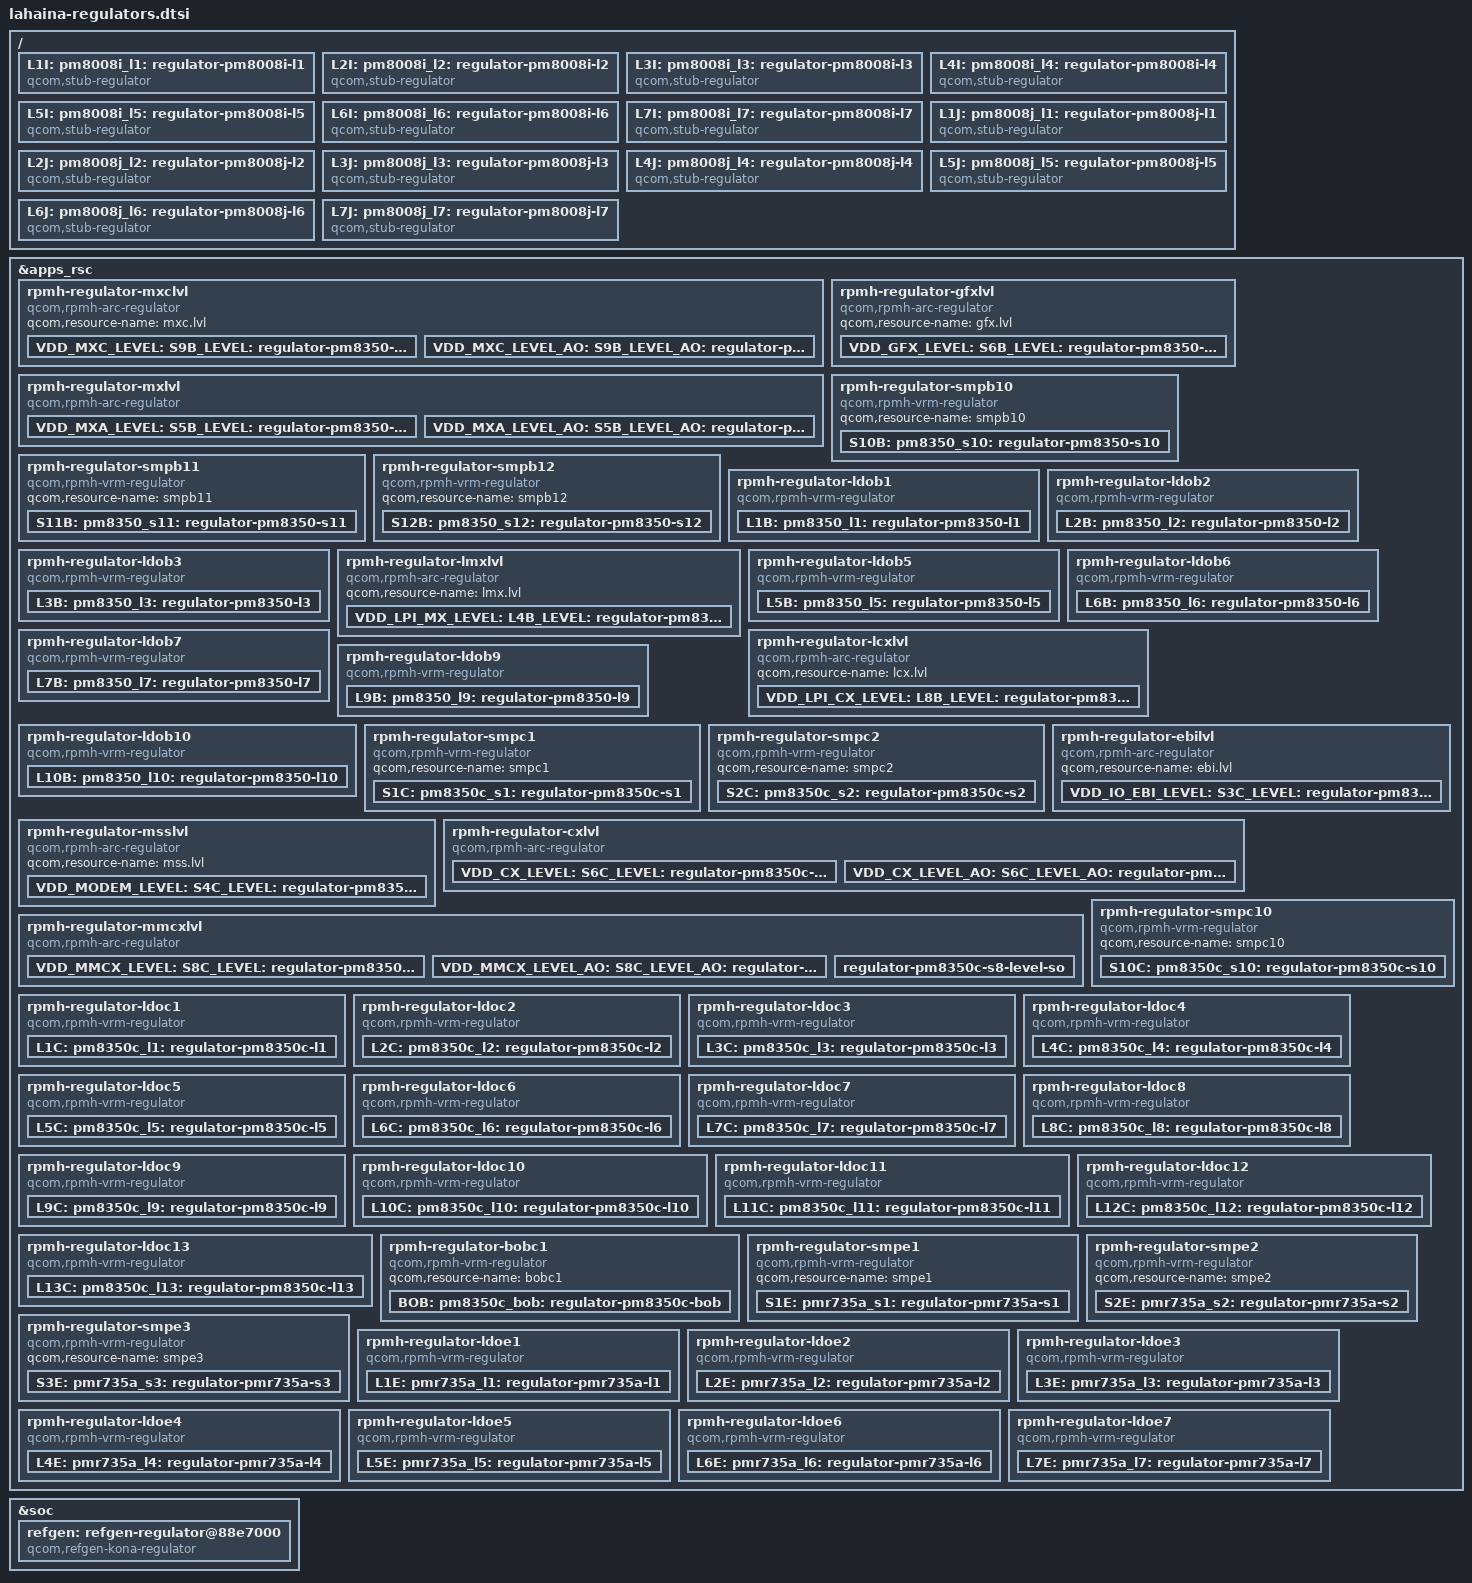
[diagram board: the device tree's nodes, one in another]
#include <dt-bindings/regulator/qcom,rpmh-regulator-levels.h>

/* RPMh regulators: */
&apps_rsc {
	rpmh-regulator-mxclvl {
		compatible = "qcom,rpmh-arc-regulator";
		qcom,resource-name = "mxc.lvl";

		VDD_MXC_LEVEL: S9B_LEVEL:
		pm8350_s9_level: regulator-pm8350-s9-level {
			regulator-name = "pm8350_s9_level";
			qcom,set = <RPMH_REGULATOR_SET_ALL>;
			regulator-min-microvolt =
				<RPMH_REGULATOR_LEVEL_TURBO>;
			regulator-max-microvolt =
				<RPMH_REGULATOR_LEVEL_MAX>;
			qcom,init-voltage-level =
				<RPMH_REGULATOR_LEVEL_TURBO>;
			regulator-always-on;
		};

		VDD_MXC_LEVEL_AO: S9B_LEVEL_AO:
		pm8350_s9_level_ao: regulator-pm8350-s9-level-ao {
			regulator-name = "pm8350_s9_level_ao";
			qcom,set = <RPMH_REGULATOR_SET_ACTIVE>;
			regulator-min-microvolt =
				<RPMH_REGULATOR_LEVEL_RETENTION>;
			regulator-max-microvolt =
				<RPMH_REGULATOR_LEVEL_MAX>;
			qcom,init-voltage-level =
				<RPMH_REGULATOR_LEVEL_RETENTION>;
		};
	};

	rpmh-regulator-mxlvl {
		compatible = "qcom,rpmh-arc-regulator";
		qcom,resource-name = "mx.lvl";
		pm8350_s5_level-parent-supply = <&VDD_MXC_LEVEL>;
		pm8350_s5_level_ao-parent-supply = <&VDD_MXC_LEVEL_AO>;

		VDD_MXA_LEVEL: S5B_LEVEL:
		pm8350_s5_level: regulator-pm8350-s5-level {
			regulator-name = "pm8350_s5_level";
			qcom,set = <RPMH_REGULATOR_SET_ALL>;
			regulator-min-microvolt =
				<RPMH_REGULATOR_LEVEL_TURBO>;
			regulator-max-microvolt =
				<RPMH_REGULATOR_LEVEL_MAX>;
			qcom,init-voltage-level =
				<RPMH_REGULATOR_LEVEL_TURBO>;
			qcom,min-dropout-voltage-level = <(-1)>;
			regulator-always-on;
		};

		VDD_MXA_LEVEL_AO: S5B_LEVEL_AO:
		pm8350_s5_level_ao: regulator-pm8350-s5-level-ao {
			regulator-name = "pm8350_s5_level_ao";
			qcom,set = <RPMH_REGULATOR_SET_ACTIVE>;
			regulator-min-microvolt =
				<RPMH_REGULATOR_LEVEL_RETENTION>;
			regulator-max-microvolt =
				<RPMH_REGULATOR_LEVEL_MAX>;
			qcom,init-voltage-level =
				<RPMH_REGULATOR_LEVEL_RETENTION>;
			qcom,min-dropout-voltage-level = <(-1)>;
		};
	};

	rpmh-regulator-gfxlvl {
		compatible = "qcom,rpmh-arc-regulator";
		qcom,resource-name = "gfx.lvl";
		VDD_GFX_LEVEL: S6B_LEVEL:
		pm8350_s6_level: regulator-pm8350-s6-level {
			regulator-name = "pm8350_s6_level";
			qcom,set = <RPMH_REGULATOR_SET_ALL>;
			regulator-min-microvolt =
				<RPMH_REGULATOR_LEVEL_RETENTION>;
			regulator-max-microvolt =
				<RPMH_REGULATOR_LEVEL_MAX>;
			qcom,init-voltage-level =
				<RPMH_REGULATOR_LEVEL_RETENTION>;
		};
	};

	rpmh-regulator-smpb10 {
		compatible = "qcom,rpmh-vrm-regulator";
		qcom,resource-name = "smpb10";
		S10B: pm8350_s10: regulator-pm8350-s10 {
			regulator-name = "pm8350_s10";
			qcom,set = <RPMH_REGULATOR_SET_ALL>;
			regulator-min-microvolt = <1726000>;
			regulator-max-microvolt = <1800000>;
			qcom,init-voltage = <1800000>;
		};
	};

	rpmh-regulator-smpb11 {
		compatible = "qcom,rpmh-vrm-regulator";
		qcom,resource-name = "smpb11";
		S11B: pm8350_s11: regulator-pm8350-s11 {
			regulator-name = "pm8350_s11";
			qcom,set = <RPMH_REGULATOR_SET_ALL>;
			regulator-min-microvolt = <870000>;
			regulator-max-microvolt = <2040000>;
			qcom,init-voltage = <952000>;
		};
	};

	rpmh-regulator-smpb12 {
		compatible = "qcom,rpmh-vrm-regulator";
		qcom,resource-name = "smpb12";
		S12B: pm8350_s12: regulator-pm8350-s12 {
			regulator-name = "pm8350_s12";
			qcom,set = <RPMH_REGULATOR_SET_ALL>;
			regulator-min-microvolt = <1170000>;
			regulator-max-microvolt = <2040000>;
			qcom,init-voltage = <1256000>;
		};
	};

	rpmh-regulator-ldob1 {
		compatible = "qcom,rpmh-vrm-regulator";
		qcom,resource-name = "ldob1";
		qcom,regulator-type = "pmic5-ldo";
		qcom,supported-modes =
			<RPMH_REGULATOR_MODE_LPM
			 RPMH_REGULATOR_MODE_HPM>;
		qcom,mode-threshold-currents = <0 30000>;
		L1B: pm8350_l1: regulator-pm8350-l1 {
			regulator-name = "pm8350_l1";
			qcom,set = <RPMH_REGULATOR_SET_ALL>;
			regulator-min-microvolt = <880000>;
			regulator-max-microvolt = <920000>;
			qcom,init-voltage = <912000>;
			qcom,init-mode = <RPMH_REGULATOR_MODE_LPM>;
		};
	};

	rpmh-regulator-ldob2 {
		compatible = "qcom,rpmh-vrm-regulator";
		qcom,resource-name = "ldob2";
		qcom,regulator-type = "pmic5-ldo";
		qcom,supported-modes =
			<RPMH_REGULATOR_MODE_LPM
			 RPMH_REGULATOR_MODE_HPM>;
		qcom,mode-threshold-currents = <0 10000>;
		L2B: pm8350_l2: regulator-pm8350-l2 {
			regulator-name = "pm8350_l2";
			qcom,set = <RPMH_REGULATOR_SET_ALL>;
			regulator-min-microvolt = <3072000>;
			regulator-max-microvolt = <3072000>;
			qcom,init-voltage = <3072000>;
			qcom,init-mode = <RPMH_REGULATOR_MODE_LPM>;
		};
	};

	rpmh-regulator-ldob3 {
		compatible = "qcom,rpmh-vrm-regulator";
		qcom,resource-name = "ldob3";
		qcom,regulator-type = "pmic5-ldo";
		qcom,supported-modes =
			<RPMH_REGULATOR_MODE_LPM
			 RPMH_REGULATOR_MODE_HPM>;
		qcom,mode-threshold-currents = <0 30000>;
		L3B: pm8350_l3: regulator-pm8350-l3 {
			regulator-name = "pm8350_l3";
			qcom,set = <RPMH_REGULATOR_SET_ALL>;
			regulator-min-microvolt = <928000>;
			regulator-max-microvolt = <928000>;
			qcom,init-voltage = <928000>;
			qcom,init-mode = <RPMH_REGULATOR_MODE_LPM>;
		};
	};

	rpmh-regulator-lmxlvl {
		compatible = "qcom,rpmh-arc-regulator";
		qcom,resource-name = "lmx.lvl";
		VDD_LPI_MX_LEVEL: L4B_LEVEL:
		pm8350_l4_level: regulator-pm8350-l4-level {
			regulator-name = "pm8350_l4_level";
			qcom,set = <RPMH_REGULATOR_SET_ALL>;
			regulator-min-microvolt =
				<RPMH_REGULATOR_LEVEL_RETENTION>;
			regulator-max-microvolt =
				<RPMH_REGULATOR_LEVEL_MAX>;
			qcom,init-voltage-level =
				<RPMH_REGULATOR_LEVEL_RETENTION>;
		};
	};

	rpmh-regulator-ldob5 {
		compatible = "qcom,rpmh-vrm-regulator";
		qcom,resource-name = "ldob5";
		qcom,regulator-type = "pmic5-ldo";
		qcom,supported-modes =
			<RPMH_REGULATOR_MODE_LPM
			 RPMH_REGULATOR_MODE_HPM>;
		qcom,mode-threshold-currents = <0 30000>;
		L5B: pm8350_l5: regulator-pm8350-l5 {
			regulator-name = "pm8350_l5";
			qcom,set = <RPMH_REGULATOR_SET_ALL>;
			regulator-min-microvolt = <880000>;
			regulator-max-microvolt = <880000>;
			qcom,init-voltage = <880000>;
			qcom,init-mode = <RPMH_REGULATOR_MODE_LPM>;
		};
	};

	rpmh-regulator-ldob6 {
		compatible = "qcom,rpmh-vrm-regulator";
		qcom,resource-name = "ldob6";
		qcom,regulator-type = "pmic5-ldo";
		qcom,supported-modes =
			<RPMH_REGULATOR_MODE_LPM
			 RPMH_REGULATOR_MODE_HPM>;
		qcom,mode-threshold-currents = <0 30000>;
		L6B: pm8350_l6: regulator-pm8350-l6 {
			regulator-name = "pm8350_l6";
			qcom,set = <RPMH_REGULATOR_SET_ALL>;
			regulator-min-microvolt = <1200000>;
			regulator-max-microvolt = <1200000>;
			qcom,init-voltage = <1200000>;
			qcom,init-mode = <RPMH_REGULATOR_MODE_LPM>;
		};
	};

	rpmh-regulator-ldob7 {
		compatible = "qcom,rpmh-vrm-regulator";
		qcom,resource-name = "ldob7";
		qcom,regulator-type = "pmic5-ldo";
		qcom,supported-modes =
			<RPMH_REGULATOR_MODE_LPM
			 RPMH_REGULATOR_MODE_HPM>;
		qcom,mode-threshold-currents = <0 10000>;
		L7B: pm8350_l7: regulator-pm8350-l7 {
			regulator-name = "pm8350_l7";
			qcom,set = <RPMH_REGULATOR_SET_ALL>;
			regulator-min-microvolt = <1704000>;
			regulator-max-microvolt = <3600000>;
			qcom,init-voltage = <2504000>;
			qcom,init-mode = <RPMH_REGULATOR_MODE_LPM>;
		};
	};

	rpmh-regulator-lcxlvl {
		compatible = "qcom,rpmh-arc-regulator";
		qcom,resource-name = "lcx.lvl";
		VDD_LPI_CX_LEVEL: L8B_LEVEL:
		pm8350_l8_level: regulator-pm8350-l8-level {
			regulator-name = "pm8350_l8_level";
			qcom,set = <RPMH_REGULATOR_SET_ALL>;
			regulator-min-microvolt =
				<RPMH_REGULATOR_LEVEL_RETENTION>;
			regulator-max-microvolt =
				<RPMH_REGULATOR_LEVEL_MAX>;
			qcom,init-voltage-level =
				<RPMH_REGULATOR_LEVEL_RETENTION>;
		};
	};

	rpmh-regulator-ldob9 {
		compatible = "qcom,rpmh-vrm-regulator";
		qcom,resource-name = "ldob9";
		qcom,regulator-type = "pmic5-ldo";
		qcom,supported-modes =
			<RPMH_REGULATOR_MODE_LPM
			 RPMH_REGULATOR_MODE_HPM>;
		qcom,mode-threshold-currents = <0 30000>;
		L9B: pm8350_l9: regulator-pm8350-l9 {
			regulator-name = "pm8350_l9";
			qcom,set = <RPMH_REGULATOR_SET_ALL>;
			regulator-min-microvolt = <1200000>;
			regulator-max-microvolt = <1200000>;
			qcom,init-voltage = <1200000>;
			qcom,init-mode = <RPMH_REGULATOR_MODE_LPM>;
		};
	};

	rpmh-regulator-ldob10 {
		compatible = "qcom,rpmh-vrm-regulator";
		qcom,resource-name = "ldob10";
		qcom,regulator-type = "pmic5-ldo";
		qcom,supported-modes =
			<RPMH_REGULATOR_MODE_LPM
			 RPMH_REGULATOR_MODE_HPM>;
		qcom,mode-threshold-currents = <0 30000>;
		L10B: pm8350_l10: regulator-pm8350-l10 {
			regulator-name = "pm8350_l10";
			qcom,set = <RPMH_REGULATOR_SET_ALL>;
			regulator-min-microvolt = <1256000>;
			regulator-max-microvolt = <1400000>;
			qcom,init-voltage = <1256000>;
			qcom,init-mode = <RPMH_REGULATOR_MODE_LPM>;
		};
	};

	rpmh-regulator-smpc1 {
		compatible = "qcom,rpmh-vrm-regulator";
		qcom,resource-name = "smpc1";
		S1C: pm8350c_s1: regulator-pm8350c-s1 {
			regulator-name = "pm8350c_s1";
			qcom,set = <RPMH_REGULATOR_SET_ALL>;
			regulator-min-microvolt = <1825000>;
			regulator-max-microvolt = <1900000>;
			qcom,init-voltage = <1856000>;
		};
	};

	rpmh-regulator-smpc2 {
		compatible = "qcom,rpmh-vrm-regulator";
		qcom,resource-name = "smpc2";
		S2C: pm8350c_s2: regulator-pm8350c-s2 {
			regulator-name = "pm8350c_s2";
			qcom,set = <RPMH_REGULATOR_SET_ALL>;
			regulator-min-microvolt = <630000>;
			regulator-max-microvolt = <1000000>;
			qcom,init-voltage = <800000>;
		};
	};

	rpmh-regulator-ebilvl {
		compatible = "qcom,rpmh-arc-regulator";
		qcom,resource-name = "ebi.lvl";
		VDD_IO_EBI_LEVEL: S3C_LEVEL:
		pm8350c_s3_level: regulator-pm8350c-s3-level {
			regulator-name = "pm8350c_s3_level";
			qcom,set = <RPMH_REGULATOR_SET_ALL>;
			regulator-min-microvolt =
				<RPMH_REGULATOR_LEVEL_RETENTION>;
			regulator-max-microvolt =
				<RPMH_REGULATOR_LEVEL_MAX>;
			qcom,init-voltage-level =
				<RPMH_REGULATOR_LEVEL_RETENTION>;
		};
	};

	rpmh-regulator-msslvl {
		compatible = "qcom,rpmh-arc-regulator";
		qcom,resource-name = "mss.lvl";
		VDD_MODEM_LEVEL: S4C_LEVEL:
		pm8350c_s4_level: regulator-pm8350c-s4-level {
			regulator-name = "pm8350c_s4_level";
			qcom,set = <RPMH_REGULATOR_SET_ALL>;
			regulator-min-microvolt =
				<RPMH_REGULATOR_LEVEL_RETENTION>;
			regulator-max-microvolt =
				<RPMH_REGULATOR_LEVEL_MAX>;
			qcom,init-voltage-level =
				<RPMH_REGULATOR_LEVEL_RETENTION>;
		};
	};

	rpmh-regulator-cxlvl {
		compatible = "qcom,rpmh-arc-regulator";
		qcom,resource-name = "cx.lvl";
		pm8350c_s6_level-parent-supply = <&VDD_MXA_LEVEL>;
		pm8350c_s6_level_ao-parent-supply = <&VDD_MXA_LEVEL_AO>;

		VDD_CX_LEVEL: S6C_LEVEL:
		pm8350c_s6_level: regulator-pm8350c-s6-level {
			regulator-name = "pm8350c_s6_level";
			qcom,set = <RPMH_REGULATOR_SET_ALL>;
			regulator-min-microvolt =
				<RPMH_REGULATOR_LEVEL_TURBO>;
			regulator-max-microvolt =
				<RPMH_REGULATOR_LEVEL_MAX>;
			qcom,init-voltage-level =
				<RPMH_REGULATOR_LEVEL_TURBO>;
			qcom,min-dropout-voltage-level = <(-1)>;
			regulator-always-on;
		};

		VDD_CX_LEVEL_AO: S6C_LEVEL_AO:
		pm8350c_s6_level_ao: regulator-pm8350c-s6-level-ao {
			regulator-name = "pm8350c_s6_level_ao";
			qcom,set = <RPMH_REGULATOR_SET_ACTIVE>;
			regulator-min-microvolt =
				<RPMH_REGULATOR_LEVEL_RETENTION>;
			regulator-max-microvolt =
				<RPMH_REGULATOR_LEVEL_MAX>;
			qcom,init-voltage-level =
				<RPMH_REGULATOR_LEVEL_RETENTION>;
			qcom,min-dropout-voltage-level = <(-1)>;
		};
	};

	rpmh-regulator-mmcxlvl {
		compatible = "qcom,rpmh-arc-regulator";
		qcom,resource-name = "mmcx.lvl";
		pm8350c_s8_level-parent-supply = <&VDD_MXA_LEVEL>;
		pm8350c_s8_level_ao-parent-supply = <&VDD_MXA_LEVEL_AO>;

		VDD_MMCX_LEVEL: S8C_LEVEL: VDD_MM_LEVEL:
		pm8350c_s8_level: regulator-pm8350c-s8-level {
			regulator-name = "pm8350c_s8_level";
			qcom,set = <RPMH_REGULATOR_SET_ALL>;
			regulator-min-microvolt =
				<RPMH_REGULATOR_LEVEL_TURBO>;
			regulator-max-microvolt =
				<RPMH_REGULATOR_LEVEL_MAX>;
			qcom,init-voltage-level =
				<RPMH_REGULATOR_LEVEL_TURBO>;
			qcom,min-dropout-voltage-level = <(-1)>;
			regulator-always-on;
		};

		VDD_MMCX_LEVEL_AO: S8C_LEVEL_AO: VDD_MM_LEVEL_AO:
		pm8350c_s8_level_ao: regulator-pm8350c-s8-level-ao {
			regulator-name = "pm8350c_s8_level_ao";
			qcom,set = <RPMH_REGULATOR_SET_ACTIVE>;
			regulator-min-microvolt =
				<RPMH_REGULATOR_LEVEL_LOW_SVS>;
			regulator-max-microvolt =
				<RPMH_REGULATOR_LEVEL_MAX>;
			qcom,init-voltage-level =
				<RPMH_REGULATOR_LEVEL_LOW_SVS>;
			qcom,min-dropout-voltage-level = <(-1)>;
		};

		regulator-pm8350c-s8-level-so {
			regulator-name = "pm8350c_s8_level_so";
			qcom,set = <RPMH_REGULATOR_SET_SLEEP>;
			regulator-min-microvolt =
				<RPMH_REGULATOR_LEVEL_LOW_SVS>;
			regulator-max-microvolt =
				<RPMH_REGULATOR_LEVEL_MAX>;
			qcom,init-voltage-level =
				<RPMH_REGULATOR_LEVEL_LOW_SVS>;
		};
	};

	rpmh-regulator-smpc10 {
		compatible = "qcom,rpmh-vrm-regulator";
		qcom,resource-name = "smpc10";
		S10C: pm8350c_s10: regulator-pm8350c-s10 {
			regulator-name = "pm8350c_s10";
			qcom,set = <RPMH_REGULATOR_SET_ALL>;
			regulator-min-microvolt = <1060000>;
			regulator-max-microvolt = <1120000>;
			qcom,init-voltage = <1060000>;
		};
	};

	rpmh-regulator-ldoc1 {
		compatible = "qcom,rpmh-vrm-regulator";
		qcom,resource-name = "ldoc1";
		qcom,regulator-type = "pmic5-ldo";
		qcom,supported-modes =
			<RPMH_REGULATOR_MODE_LPM
			 RPMH_REGULATOR_MODE_HPM>;
		qcom,mode-threshold-currents = <0 10000>;
		L1C: pm8350c_l1: regulator-pm8350c-l1 {
			regulator-name = "pm8350c_l1";
			qcom,set = <RPMH_REGULATOR_SET_ALL>;
			regulator-min-microvolt = <1800000>;
			regulator-max-microvolt = <1800000>;
			qcom,init-voltage = <1800000>;
			qcom,init-mode = <RPMH_REGULATOR_MODE_LPM>;
		};
	};

	rpmh-regulator-ldoc2 {
		compatible = "qcom,rpmh-vrm-regulator";
		qcom,resource-name = "ldoc2";
		qcom,regulator-type = "pmic5-ldo";
		qcom,supported-modes =
			<RPMH_REGULATOR_MODE_LPM
			 RPMH_REGULATOR_MODE_HPM>;
		qcom,mode-threshold-currents = <0 10000>;
		L2C: pm8350c_l2: regulator-pm8350c-l2 {
			regulator-name = "pm8350c_l2";
			qcom,set = <RPMH_REGULATOR_SET_ALL>;
			regulator-min-microvolt = <1800000>;
			regulator-max-microvolt = <1800000>;
			qcom,init-voltage = <1800000>;
			qcom,init-mode = <RPMH_REGULATOR_MODE_LPM>;
		};
	};

	rpmh-regulator-ldoc3 {
		compatible = "qcom,rpmh-vrm-regulator";
		qcom,resource-name = "ldoc3";
		qcom,regulator-type = "pmic5-ldo";
		qcom,supported-modes =
			<RPMH_REGULATOR_MODE_LPM
			 RPMH_REGULATOR_MODE_HPM>;
		qcom,mode-threshold-currents = <0 10000>;
		L3C: pm8350c_l3: regulator-pm8350c-l3 {
			regulator-name = "pm8350c_l3";
			qcom,set = <RPMH_REGULATOR_SET_ALL>;
			regulator-min-microvolt = <3008000>;
			regulator-max-microvolt = <3008000>;
			qcom,init-voltage = <3008000>;
			qcom,init-mode = <RPMH_REGULATOR_MODE_LPM>;
		};
	};

	rpmh-regulator-ldoc4 {
		compatible = "qcom,rpmh-vrm-regulator";
		qcom,resource-name = "ldoc4";
		qcom,regulator-type = "pmic5-ldo";
		qcom,supported-modes =
			<RPMH_REGULATOR_MODE_LPM
			 RPMH_REGULATOR_MODE_HPM>;
		qcom,mode-threshold-currents = <0 10000>;
		L4C: pm8350c_l4: regulator-pm8350c-l4 {
			regulator-name = "pm8350c_l4";
			qcom,set = <RPMH_REGULATOR_SET_ALL>;
			regulator-min-microvolt = <1800000>;
			regulator-max-microvolt = <2800000>;
			qcom,init-voltage = <1808000>;
			qcom,init-mode = <RPMH_REGULATOR_MODE_LPM>;
		};
	};

	rpmh-regulator-ldoc5 {
		compatible = "qcom,rpmh-vrm-regulator";
		qcom,resource-name = "ldoc5";
		qcom,regulator-type = "pmic5-ldo";
		qcom,supported-modes =
			<RPMH_REGULATOR_MODE_LPM
			 RPMH_REGULATOR_MODE_HPM>;
		qcom,mode-threshold-currents = <0 10000>;
		L5C: pm8350c_l5: regulator-pm8350c-l5 {
			regulator-name = "pm8350c_l5";
			qcom,set = <RPMH_REGULATOR_SET_ALL>;
			regulator-min-microvolt = <1800000>;
			regulator-max-microvolt = <2800000>;
			qcom,init-voltage = <1808000>;
			qcom,init-mode = <RPMH_REGULATOR_MODE_LPM>;
		};
	};

	rpmh-regulator-ldoc6 {
		compatible = "qcom,rpmh-vrm-regulator";
		qcom,resource-name = "ldoc6";
		qcom,regulator-type = "pmic5-ldo";
		qcom,supported-modes =
			<RPMH_REGULATOR_MODE_LPM
			 RPMH_REGULATOR_MODE_HPM>;
		qcom,mode-threshold-currents = <0 10000>;
		L6C: pm8350c_l6: regulator-pm8350c-l6 {
			regulator-name = "pm8350c_l6";
			qcom,set = <RPMH_REGULATOR_SET_ALL>;
			regulator-min-microvolt = <1800000>;
			regulator-max-microvolt = <2960000>;
			qcom,init-voltage = <1800000>;
			qcom,init-mode = <RPMH_REGULATOR_MODE_LPM>;
		};
	};

	rpmh-regulator-ldoc7 {
		compatible = "qcom,rpmh-vrm-regulator";
		qcom,resource-name = "ldoc7";
		qcom,regulator-type = "pmic5-ldo";
		qcom,supported-modes =
			<RPMH_REGULATOR_MODE_LPM
			 RPMH_REGULATOR_MODE_HPM>;
		qcom,mode-threshold-currents = <0 10000>;
		L7C: pm8350c_l7: regulator-pm8350c-l7 {
			regulator-name = "pm8350c_l7";
			qcom,set = <RPMH_REGULATOR_SET_ALL>;
			regulator-min-microvolt = <2856000>;
			regulator-max-microvolt = <3104000>;
			qcom,init-voltage = <3008000>;
			qcom,init-mode = <RPMH_REGULATOR_MODE_LPM>;
		};
	};

	rpmh-regulator-ldoc8 {
		compatible = "qcom,rpmh-vrm-regulator";
		qcom,resource-name = "ldoc8";
		qcom,regulator-type = "pmic5-ldo";
		qcom,supported-modes =
			<RPMH_REGULATOR_MODE_LPM
			 RPMH_REGULATOR_MODE_HPM>;
		qcom,mode-threshold-currents = <0 10000>;
		L8C: pm8350c_l8: regulator-pm8350c-l8 {
			regulator-name = "pm8350c_l8";
			qcom,set = <RPMH_REGULATOR_SET_ALL>;
			regulator-min-microvolt = <1800000>;
			regulator-max-microvolt = <1800000>;
			qcom,init-voltage = <1800000>;
			qcom,init-mode = <RPMH_REGULATOR_MODE_LPM>;
		};
	};

	rpmh-regulator-ldoc9 {
		compatible = "qcom,rpmh-vrm-regulator";
		qcom,resource-name = "ldoc9";
		qcom,regulator-type = "pmic5-ldo";
		qcom,supported-modes =
			<RPMH_REGULATOR_MODE_LPM
			 RPMH_REGULATOR_MODE_HPM>;
		qcom,mode-threshold-currents = <0 10000>;
		L9C: pm8350c_l9: regulator-pm8350c-l9 {
			regulator-name = "pm8350c_l9";
			qcom,set = <RPMH_REGULATOR_SET_ALL>;
			regulator-min-microvolt = <2704000>;
			regulator-max-microvolt = <2960000>;
			qcom,init-voltage = <2960000>;
			qcom,init-mode = <RPMH_REGULATOR_MODE_LPM>;
		};
	};

	rpmh-regulator-ldoc10 {
		compatible = "qcom,rpmh-vrm-regulator";
		qcom,resource-name = "ldoc10";
		qcom,regulator-type = "pmic5-ldo";
		qcom,supported-modes =
			<RPMH_REGULATOR_MODE_LPM
			 RPMH_REGULATOR_MODE_HPM>;
		qcom,mode-threshold-currents = <0 30000>;
		L10C: pm8350c_l10: regulator-pm8350c-l10 {
			regulator-name = "pm8350c_l10";
			qcom,set = <RPMH_REGULATOR_SET_ALL>;
			regulator-min-microvolt = <1200000>;
			regulator-max-microvolt = <1200000>;
			qcom,init-voltage = <1200000>;
			qcom,init-mode = <RPMH_REGULATOR_MODE_LPM>;
		};
	};

	rpmh-regulator-ldoc11 {
		compatible = "qcom,rpmh-vrm-regulator";
		qcom,resource-name = "ldoc11";
		qcom,regulator-type = "pmic5-ldo";
		qcom,supported-modes =
			<RPMH_REGULATOR_MODE_LPM
			 RPMH_REGULATOR_MODE_HPM>;
		qcom,mode-threshold-currents = <0 10000>;
		L11C: pm8350c_l11: regulator-pm8350c-l11 {
			regulator-name = "pm8350c_l11";
			qcom,set = <RPMH_REGULATOR_SET_ALL>;
			regulator-min-microvolt = <2504000>;
			regulator-max-microvolt = <3304000>;
			qcom,init-voltage = <2504000>;
			qcom,init-mode = <RPMH_REGULATOR_MODE_LPM>;
		};
	};

	rpmh-regulator-ldoc12 {
		compatible = "qcom,rpmh-vrm-regulator";
		qcom,resource-name = "ldoc12";
		qcom,regulator-type = "pmic5-ldo";
		qcom,supported-modes =
			<RPMH_REGULATOR_MODE_LPM
			 RPMH_REGULATOR_MODE_HPM>;
		qcom,mode-threshold-currents = <0 10000>;
		L12C: pm8350c_l12: regulator-pm8350c-l12 {
			regulator-name = "pm8350c_l12";
			qcom,set = <RPMH_REGULATOR_SET_ALL>;
			regulator-min-microvolt = <1800000>;
			regulator-max-microvolt = <1800000>;
			qcom,init-voltage = <1800000>;
			qcom,init-mode = <RPMH_REGULATOR_MODE_LPM>;
		};
	};

	rpmh-regulator-ldoc13 {
		compatible = "qcom,rpmh-vrm-regulator";
		qcom,resource-name = "ldoc13";
		qcom,regulator-type = "pmic5-ldo";
		qcom,supported-modes =
			<RPMH_REGULATOR_MODE_LPM
			 RPMH_REGULATOR_MODE_HPM>;
		qcom,mode-threshold-currents = <0 10000>;
		L13C: pm8350c_l13: regulator-pm8350c-l13 {
			regulator-name = "pm8350c_l13";
			qcom,set = <RPMH_REGULATOR_SET_ALL>;
			regulator-min-microvolt = <3000000>;
			regulator-max-microvolt = <3312000>;
			qcom,init-voltage = <3000000>;
			qcom,init-mode = <RPMH_REGULATOR_MODE_LPM>;
		};
	};

	rpmh-regulator-bobc1 {
		compatible = "qcom,rpmh-vrm-regulator";
		qcom,resource-name = "bobc1";
		BOB: pm8350c_bob: regulator-pm8350c-bob {
			regulator-name = "pm8350c_bob";
			qcom,set = <RPMH_REGULATOR_SET_ALL>;
			regulator-min-microvolt = <3008000>;
			regulator-max-microvolt = <3960000>;
			qcom,init-voltage = <3008000>;
		};
	};

	rpmh-regulator-smpe1 {
		compatible = "qcom,rpmh-vrm-regulator";
		qcom,resource-name = "smpe1";
		S1E: pmr735a_s1: regulator-pmr735a-s1 {
			regulator-name = "pmr735a_s1";
			qcom,set = <RPMH_REGULATOR_SET_ALL>;
			regulator-min-microvolt = <1140000>;
			regulator-max-microvolt = <1352000>;
			qcom,init-voltage = <1256000>;
		};
	};

	rpmh-regulator-smpe2 {
		compatible = "qcom,rpmh-vrm-regulator";
		qcom,resource-name = "smpe2";
		S2E: pmr735a_s2: regulator-pmr735a-s2 {
			regulator-name = "pmr735a_s2";
			qcom,set = <RPMH_REGULATOR_SET_ALL>;
			regulator-min-microvolt = <829000>;
			regulator-max-microvolt = <1352000>;
			qcom,init-voltage = <852000>;
		};
	};

	rpmh-regulator-smpe3 {
		compatible = "qcom,rpmh-vrm-regulator";
		qcom,resource-name = "smpe3";
		S3E: pmr735a_s3: regulator-pmr735a-s3 {
			regulator-name = "pmr735a_s3";
			qcom,set = <RPMH_REGULATOR_SET_ALL>;
			regulator-min-microvolt = <2000000>;
			regulator-max-microvolt = <2400000>;
			qcom,init-voltage = <2200000>;
		};
	};

	rpmh-regulator-ldoe1 {
		compatible = "qcom,rpmh-vrm-regulator";
		qcom,resource-name = "ldoe1";
		qcom,regulator-type = "pmic5-ldo";
		qcom,supported-modes =
			<RPMH_REGULATOR_MODE_LPM
			 RPMH_REGULATOR_MODE_HPM>;
		qcom,mode-threshold-currents = <0 30000>;
		L1E: pmr735a_l1: regulator-pmr735a-l1 {
			regulator-name = "pmr735a_l1";
			qcom,set = <RPMH_REGULATOR_SET_ALL>;
			regulator-min-microvolt = <880000>;
			regulator-max-microvolt = <880000>;
			qcom,init-voltage = <880000>;
			qcom,init-mode = <RPMH_REGULATOR_MODE_LPM>;
		};
	};

	rpmh-regulator-ldoe2 {
		compatible = "qcom,rpmh-vrm-regulator";
		qcom,resource-name = "ldoe2";
		qcom,regulator-type = "pmic5-ldo";
		qcom,supported-modes =
			<RPMH_REGULATOR_MODE_LPM
			 RPMH_REGULATOR_MODE_HPM>;
		qcom,mode-threshold-currents = <0 30000>;
		L2E: pmr735a_l2: regulator-pmr735a-l2 {
			regulator-name = "pmr735a_l2";
			qcom,set = <RPMH_REGULATOR_SET_ALL>;
			regulator-min-microvolt = <1200000>;
			regulator-max-microvolt = <1200000>;
			qcom,init-voltage = <1200000>;
			qcom,init-mode = <RPMH_REGULATOR_MODE_LPM>;
		};
	};

	rpmh-regulator-ldoe3 {
		compatible = "qcom,rpmh-vrm-regulator";
		qcom,resource-name = "ldoe3";
		qcom,regulator-type = "pmic5-ldo";
		qcom,supported-modes =
			<RPMH_REGULATOR_MODE_LPM
			 RPMH_REGULATOR_MODE_HPM>;
		qcom,mode-threshold-currents = <0 30000>;
		L3E: pmr735a_l3: regulator-pmr735a-l3 {
			regulator-name = "pmr735a_l3";
			qcom,set = <RPMH_REGULATOR_SET_ALL>;
			regulator-min-microvolt = <1056000>;
			regulator-max-microvolt = <1800000>;
			qcom,init-voltage = <1200000>;
			qcom,init-mode = <RPMH_REGULATOR_MODE_LPM>;
		};
	};

	rpmh-regulator-ldoe4 {
		compatible = "qcom,rpmh-vrm-regulator";
		qcom,resource-name = "ldoe4";
		qcom,regulator-type = "pmic5-ldo";
		qcom,supported-modes =
			<RPMH_REGULATOR_MODE_LPM
			 RPMH_REGULATOR_MODE_HPM>;
		qcom,mode-threshold-currents = <0 10000>;
		L4E: pmr735a_l4: regulator-pmr735a-l4 {
			regulator-name = "pmr735a_l4";
			qcom,set = <RPMH_REGULATOR_SET_ALL>;
			regulator-min-microvolt = <1056000>;
			regulator-max-microvolt = <2000000>;
			qcom,init-voltage = <1776000>;
			qcom,init-mode = <RPMH_REGULATOR_MODE_LPM>;
		};
	};

	rpmh-regulator-ldoe5 {
		compatible = "qcom,rpmh-vrm-regulator";
		qcom,resource-name = "ldoe5";
		qcom,regulator-type = "pmic5-ldo";
		qcom,supported-modes =
			<RPMH_REGULATOR_MODE_LPM
			 RPMH_REGULATOR_MODE_HPM>;
		qcom,mode-threshold-currents = <0 30000>;
		L5E: pmr735a_l5: regulator-pmr735a-l5 {
			regulator-name = "pmr735a_l5";
			qcom,set = <RPMH_REGULATOR_SET_ALL>;
			regulator-min-microvolt = <800000>;
			regulator-max-microvolt = <800000>;
			qcom,init-voltage = <800000>;
			qcom,init-mode = <RPMH_REGULATOR_MODE_LPM>;
		};
	};

	rpmh-regulator-ldoe6 {
		compatible = "qcom,rpmh-vrm-regulator";
		qcom,resource-name = "ldoe6";
		qcom,regulator-type = "pmic5-ldo";
		qcom,supported-modes =
			<RPMH_REGULATOR_MODE_LPM
			 RPMH_REGULATOR_MODE_HPM>;
		qcom,mode-threshold-currents = <0 30000>;
		L6E: pmr735a_l6: regulator-pmr735a-l6 {
			regulator-name = "pmr735a_l6";
			qcom,set = <RPMH_REGULATOR_SET_ALL>;
			regulator-min-microvolt = <652000>;
			regulator-max-microvolt = <800000>;
			qcom,init-voltage = <800000>;
			qcom,init-mode = <RPMH_REGULATOR_MODE_LPM>;
		};
	};

	rpmh-regulator-ldoe7 {
		compatible = "qcom,rpmh-vrm-regulator";
		qcom,resource-name = "ldoe7";
		qcom,regulator-type = "pmic5-ldo";
		qcom,supported-modes =
			<RPMH_REGULATOR_MODE_LPM
			 RPMH_REGULATOR_MODE_HPM>;
		qcom,mode-threshold-currents = <0 10000>;
		L7E: pmr735a_l7: regulator-pmr735a-l7 {
			regulator-name = "pmr735a_l7";
			qcom,set = <RPMH_REGULATOR_SET_ALL>;
			regulator-min-microvolt = <2800000>;
			regulator-max-microvolt = <2800000>;
			qcom,init-voltage = <2800000>;
			qcom,init-mode = <RPMH_REGULATOR_MODE_LPM>;
		};
	};
};

/* Stub regulators: */
/ {
	L1I: pm8008i_l1: regulator-pm8008i-l1 {
		compatible = "qcom,stub-regulator";
		regulator-name = "pm8008i_l1";
		regulator-min-microvolt = <1000000>;
		regulator-max-microvolt = <1200000>;
		qcom,hpm-min-load = <30000>;
	};

	L2I: pm8008i_l2: regulator-pm8008i-l2 {
		compatible = "qcom,stub-regulator";
		regulator-name = "pm8008i_l2";
		regulator-min-microvolt = <950000>;
		regulator-max-microvolt = <1150000>;
		qcom,hpm-min-load = <30000>;
	};

	L3I: pm8008i_l3: regulator-pm8008i-l3 {
		compatible = "qcom,stub-regulator";
		regulator-name = "pm8008i_l3";
		regulator-min-microvolt = <2700000>;
		regulator-max-microvolt = <3000000>;
		qcom,hpm-min-load = <10000>;
	};

	L4I: pm8008i_l4: regulator-pm8008i-l4 {
		compatible = "qcom,stub-regulator";
		regulator-name = "pm8008i_l4";
		regulator-min-microvolt = <2700000>;
		regulator-max-microvolt = <2900000>;
		qcom,hpm-min-load = <10000>;
	};

	L5I: pm8008i_l5: regulator-pm8008i-l5 {
		compatible = "qcom,stub-regulator";
		regulator-name = "pm8008i_l5";
		regulator-min-microvolt = <1700000>;
		regulator-max-microvolt = <1900000>;
		qcom,hpm-min-load = <10000>;
	};

	L6I: pm8008i_l6: regulator-pm8008i-l6 {
		compatible = "qcom,stub-regulator";
		regulator-name = "pm8008i_l6";
		regulator-min-microvolt = <2700000>;
		regulator-max-microvolt = <2900000>;
		qcom,hpm-min-load = <10000>;
	};

	L7I: pm8008i_l7: regulator-pm8008i-l7 {
		compatible = "qcom,stub-regulator";
		regulator-name = "pm8008i_l7";
		regulator-min-microvolt = <2700000>;
		regulator-max-microvolt = <3000000>;
		qcom,hpm-min-load = <10000>;
	};

	L1J: pm8008j_l1: regulator-pm8008j-l1 {
		compatible = "qcom,stub-regulator";
		regulator-name = "pm8008j_l1";
		regulator-min-microvolt = <950000>;
		regulator-max-microvolt = <1150000>;
		qcom,hpm-min-load = <30000>;
	};

	L2J: pm8008j_l2: regulator-pm8008j-l2 {
		compatible = "qcom,stub-regulator";
		regulator-name = "pm8008j_l2";
		regulator-min-microvolt = <950000>;
		regulator-max-microvolt = <1150000>;
		qcom,hpm-min-load = <30000>;
	};

	L3J: pm8008j_l3: regulator-pm8008j-l3 {
		compatible = "qcom,stub-regulator";
		regulator-name = "pm8008j_l3";
		regulator-min-microvolt = <1800000>;
		regulator-max-microvolt = <1800000>;
		qcom,hpm-min-load = <10000>;
	};

	L4J: pm8008j_l4: regulator-pm8008j-l4 {
		compatible = "qcom,stub-regulator";
		regulator-name = "pm8008j_l4";
		regulator-min-microvolt = <1800000>;
		regulator-max-microvolt = <1800000>;
		qcom,hpm-min-load = <10000>;
	};

	L5J: pm8008j_l5: regulator-pm8008j-l5 {
		compatible = "qcom,stub-regulator";
		regulator-name = "pm8008j_l5";
		regulator-min-microvolt = <2700000>;
		regulator-max-microvolt = <2900000>;
		qcom,hpm-min-load = <10000>;
	};

	L6J: pm8008j_l6: regulator-pm8008j-l6 {
		compatible = "qcom,stub-regulator";
		regulator-name = "pm8008j_l6";
		regulator-min-microvolt = <2800000>;
		regulator-max-microvolt = <2800000>;
		qcom,hpm-min-load = <10000>;
	};

	L7J: pm8008j_l7: regulator-pm8008j-l7 {
		compatible = "qcom,stub-regulator";
		regulator-name = "pm8008j_l7";
		regulator-min-microvolt = <3000000>;
		regulator-max-microvolt = <3600000>;
		qcom,hpm-min-load = <10000>;
	};
};

&soc {
	refgen: refgen-regulator@88e7000 {
		compatible = "qcom,refgen-kona-regulator";
		reg = <0x88e7000 0x84>;
		regulator-name = "refgen";
		regulator-enable-ramp-delay = <5>;
	};
};
